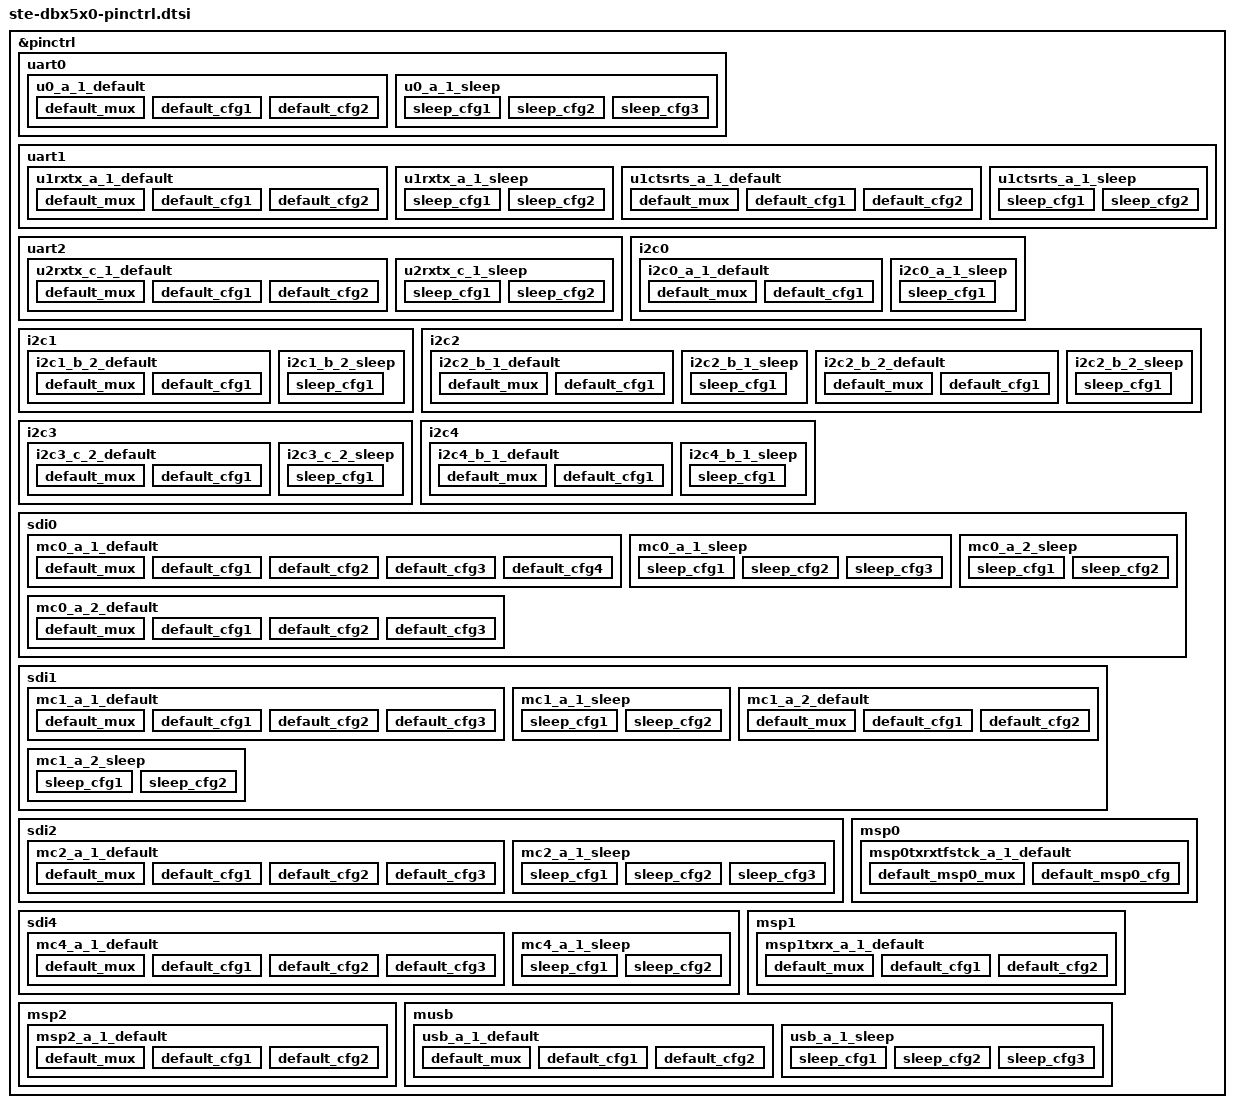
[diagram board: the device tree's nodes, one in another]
#include "ste-nomadik-pinctrl.dtsi"
&pinctrl {
	uart0 {
		u0_a_1_default: u0_a_1_default {
			default_mux {
				function = "u0";
				groups = "u0_a_1";
			};
			default_cfg1 {
				pins = "GPIO0_AJ5", "GPIO2_AH4";  
				ste,config = <&in_pu>;
			};
			default_cfg2 {
				pins = "GPIO1_AJ3", "GPIO3_AH3";  
				ste,config = <&out_hi>;
			};
		};
		u0_a_1_sleep: u0_a_1_sleep {
			sleep_cfg1 {
				pins = "GPIO0_AJ5", "GPIO2_AH4";  
				ste,config = <&slpm_in_wkup_pdis>;
			};
			sleep_cfg2 {
				pins = "GPIO1_AJ3";  
				ste,config = <&slpm_out_hi_wkup_pdis>;
			};
			sleep_cfg3 {
				pins = "GPIO3_AH3";  
				ste,config = <&slpm_out_wkup_pdis>;
			};
		};
	};
	uart1 {
		u1rxtx_a_1_default: u1rxtx_a_1_default {
			default_mux {
				function = "u1";
				groups = "u1rxtx_a_1";
			};
			default_cfg1 {
				pins = "GPIO4_AH6";  
				ste,config = <&in_pu>;
			};
			default_cfg2 {
				pins = "GPIO5_AG6";  
				ste,config = <&out_hi>;
			};
		};
		u1rxtx_a_1_sleep: u1rxtx_a_1_sleep {
			sleep_cfg1 {
				pins = "GPIO4_AH6";  
				ste,config = <&slpm_in_wkup_pdis>;
			};
			sleep_cfg2 {
				pins = "GPIO5_AG6";  
				ste,config = <&slpm_out_wkup_pdis>;
			};
		};
		u1ctsrts_a_1_default: u1ctsrts_a_1_default {
			default_mux {
				function = "u1";
				groups = "u1ctsrts_a_1";
			};
			default_cfg1 {
				pins = "GPIO6_AF6";  
				ste,config = <&in_pu>;
			};
			default_cfg2 {
				pins = "GPIO7_AG5";  
				ste,config = <&out_hi>;
			};
		};
		u1ctsrts_a_1_sleep: u1ctsrts_a_1_sleep {
			sleep_cfg1 {
				pins = "GPIO6_AF6";  
				ste,config = <&slpm_in_wkup_pdis>;
			};
			sleep_cfg2 {
				pins = "GPIO7_AG5";  
				ste,config = <&slpm_out_hi_wkup_pdis>;
			};
		};
	};
	uart2 {
		u2rxtx_c_1_default: u2rxtx_c_1_default {
			default_mux {
				function = "u2";
				groups = "u2rxtx_c_1";
			};
			default_cfg1 {
				pins = "GPIO29_W2";  
				ste,config = <&in_pu>;
			};
			default_cfg2 {
				pins = "GPIO30_W3";  
				ste,config = <&out_hi>;
			};
		};
		u2rxtx_c_1_sleep: u2rxtx_c_1_sleep {
			sleep_cfg1 {
				pins = "GPIO29_W2";  
				ste,config = <&in_wkup_pdis>;
			};
			sleep_cfg2 {
				pins = "GPIO30_W3";  
				ste,config = <&out_wkup_pdis>;
			};
		};
	};
	i2c0 {
		i2c0_a_1_default: i2c0_a_1_default {
			default_mux {
				function = "i2c0";
				groups = "i2c0_a_1";
			};
			default_cfg1 {
				pins = "GPIO147_C15", "GPIO148_B16";  
				ste,config = <&in_nopull>;
			};
		};
		i2c0_a_1_sleep: i2c0_a_1_sleep {
			sleep_cfg1 {
				pins = "GPIO147_C15", "GPIO148_B16";  
				ste,config = <&slpm_in_wkup_pdis>;
			};
		};
	};
	i2c1 {
		i2c1_b_2_default: i2c1_b_2_default {
			default_mux {
				function = "i2c1";
				groups = "i2c1_b_2";
			};
			default_cfg1 {
				pins = "GPIO16_AD3", "GPIO17_AD4";  
				ste,config = <&in_nopull>;
			};
		};
		i2c1_b_2_sleep: i2c1_b_2_sleep {
			sleep_cfg1 {
				pins = "GPIO16_AD3", "GPIO17_AD4";  
				ste,config = <&slpm_in_wkup_pdis>;
			};
		};
	};
	i2c2 {
		i2c2_b_1_default: i2c2_b_1_default {
			default_mux {
				function = "i2c2";
				groups = "i2c2_b_1";
			};
			default_cfg1 {
				pins = "GPIO8_AD5", "GPIO9_AE4";  
				ste,config = <&in_nopull>;
			};
		};
		i2c2_b_1_sleep: i2c2_b_1_sleep {
			sleep_cfg1 {
				pins = "GPIO8_AD5", "GPIO9_AE4";  
				ste,config = <&slpm_in_wkup_pdis>;
			};
		};
		i2c2_b_2_default: i2c2_b_2_default {
			default_mux {
				function = "i2c2";
				groups = "i2c2_b_2";
			};
			default_cfg1 {
				pins = "GPIO10_AF5", "GPIO11_AG4";  
				ste,config = <&in_nopull>;
			};
		};
		i2c2_b_2_sleep: i2c2_b_2_sleep {
			sleep_cfg1 {
				pins = "GPIO10_AF5", "GPIO11_AG4";  
				ste,config = <&slpm_in_wkup_pdis>;
			};
		};
	};
	i2c3 {
		i2c3_c_2_default: i2c3_c_2_default {
			default_mux {
				function = "i2c3";
				groups = "i2c3_c_2";
			};
			default_cfg1 {
				pins = "GPIO229_AG7", "GPIO230_AF7";  
				ste,config = <&in_nopull>;
			};
		};
		i2c3_c_2_sleep: i2c3_c_2_sleep {
			sleep_cfg1 {
				pins = "GPIO229_AG7", "GPIO230_AF7";  
				ste,config = <&slpm_in_wkup_pdis>;
			};
		};
	};
	i2c4 {
		i2c4_b_1_default: i2c4_b_1_default {
			default_mux {
				function = "i2c4";
				groups = "i2c4_b_1";
			};
			default_cfg1 {
				pins = "GPIO4_AH6", "GPIO5_AG6";  
				ste,config = <&in_nopull>;
			};
		};
		i2c4_b_1_sleep: i2c4_b_1_sleep {
			sleep_cfg1 {
				pins = "GPIO4_AH6", "GPIO5_AG6";  
				ste,config = <&slpm_in_wkup_pdis>;
			};
		};
	};
	sdi0 {
		mc0_a_1_default: mc0_a_1_default {
			default_mux {
				function = "mc0";
				groups = "mc0_a_1";
			};
			default_cfg1 {
				pins =
				"GPIO18_AC2",  
				"GPIO19_AC1",  
				"GPIO20_AB4";  
				ste,config = <&out_hi>;
			};
			default_cfg2 {
				pins = "GPIO22_AA3";  
				ste,config = <&in_nopull>;
			};
			default_cfg3 {
				pins = "GPIO23_AA4";  
				ste,config = <&out_lo>;
			};
			default_cfg4 {
				pins =
				"GPIO24_AB2",  
				"GPIO25_Y4",  
				"GPIO26_Y2",  
				"GPIO27_AA2",  
				"GPIO28_AA1";  
				ste,config = <&in_pu>;
			};
		};
		mc0_a_1_sleep: mc0_a_1_sleep {
			sleep_cfg1 {
				pins =
				"GPIO18_AC2",  
				"GPIO19_AC1",  
				"GPIO20_AB4";  
				ste,config = <&slpm_out_hi_wkup_pdis>;
			};
			sleep_cfg2 {
				pins =
				"GPIO22_AA3",  
				"GPIO24_AB2",  
				"GPIO25_Y4",  
				"GPIO26_Y2",  
				"GPIO27_AA2",  
				"GPIO28_AA1";  
				ste,config = <&slpm_in_wkup_pdis>;
			};
			sleep_cfg3 {
				pins = "GPIO23_AA4";  
				ste,config = <&slpm_out_lo_wkup_pdis>;
			};
		};
		mc0_a_2_default: mc0_a_2_default {
			default_mux {
				function = "mc0";
				groups = "mc0_a_2";
			};
			default_cfg1 {
				pins = "GPIO22_AA3";  
				ste,config = <&in_nopull>;
			};
			default_cfg2 {
				pins = "GPIO23_AA4";  
				ste,config = <&out_lo>;
			};
			default_cfg3 {
				pins =
				"GPIO24_AB2",  
				"GPIO25_Y4",  
				"GPIO26_Y2",  
				"GPIO27_AA2",  
				"GPIO28_AA1";  
				ste,config = <&in_pu>;
			};
		};
		mc0_a_2_sleep: mc0_a_2_sleep {
			sleep_cfg1 {
				pins =
				"GPIO22_AA3",  
				"GPIO24_AB2",  
				"GPIO25_Y4",  
				"GPIO26_Y2",  
				"GPIO27_AA2",  
				"GPIO28_AA1";  
				ste,config = <&slpm_in_wkup_pdis>;
			};
			sleep_cfg2 {
				pins = "GPIO23_AA4";  
				ste,config = <&slpm_out_lo_wkup_pdis>;
			};
		};
	};
	sdi1 {
		mc1_a_1_default: mc1_a_1_default {
			default_mux {
				function = "mc1";
				groups = "mc1_a_1";
			};
			default_cfg1 {
				pins = "GPIO208_AH16";  
				ste,config = <&out_lo>;
			};
			default_cfg2 {
				pins = "GPIO209_AG15";  
				ste,config = <&in_nopull>;
			};
			default_cfg3 {
				pins =
				"GPIO210_AJ15",  
				"GPIO211_AG14",  
				"GPIO212_AF13",  
				"GPIO213_AG13",  
				"GPIO214_AH15";  
				ste,config = <&in_pu>;
			};
		};
		mc1_a_1_sleep: mc1_a_1_sleep {
			sleep_cfg1 {
				pins = "GPIO208_AH16";  
				ste,config = <&slpm_out_lo_wkup_pdis>;
			};
			sleep_cfg2 {
				pins =
				"GPIO209_AG15",  
				"GPIO210_AJ15",  
				"GPIO211_AG14",  
				"GPIO212_AF13",  
				"GPIO213_AG13",  
				"GPIO214_AH15";  
				ste,config = <&slpm_in_wkup_pdis>;
			};
		};
		mc1_a_2_default: mc1_a_2_default {
			default_mux {
				function = "mc1";
				groups = "mc1_a_2";
			};
			default_cfg1 {
				pins = "GPIO208_AH16";  
				ste,config = <&out_lo>;
			};
			default_cfg2 {
				pins =
				"GPIO210_AJ15",  
				"GPIO211_AG14",  
				"GPIO212_AF13",  
				"GPIO213_AG13",  
				"GPIO214_AH15";  
				ste,config = <&in_pu>;
			};
		};
		mc1_a_2_sleep: mc1_a_2_sleep {
			sleep_cfg1 {
				pins = "GPIO208_AH16";  
				ste,config = <&slpm_out_lo_wkup_pdis>;
			};
			sleep_cfg2 {
				pins =
				"GPIO210_AJ15",  
				"GPIO211_AG14",  
				"GPIO212_AF13",  
				"GPIO213_AG13",  
				"GPIO214_AH15";  
				ste,config = <&slpm_in_wkup_pdis>;
			};
		};
	};
	sdi2 {
		mc2_a_1_default: mc2_a_1_default {
			default_mux {
				function = "mc2";
				groups = "mc2_a_1";
			};
			default_cfg1 {
				pins = "GPIO128_A5";  
				ste,config = <&out_lo>;
			};
			default_cfg2 {
				pins = "GPIO130_C8";  
				ste,config = <&in_nopull>;
			};
			default_cfg3 {
				pins =
				"GPIO129_B4",  
				"GPIO131_A12",  
				"GPIO132_C10",  
				"GPIO133_B10",  
				"GPIO134_B9",  
				"GPIO135_A9",  
				"GPIO136_C7",  
				"GPIO137_A7",  
				"GPIO138_C5";  
				ste,config = <&in_pu>;
			};
		};
		mc2_a_1_sleep: mc2_a_1_sleep {
			sleep_cfg1 {
				pins = "GPIO128_A5";  
				ste,config = <&out_lo_wkup_pdis>;
			};
			sleep_cfg2 {
				pins =
				"GPIO130_C8",  
				"GPIO129_B4";  
				ste,config = <&in_wkup_pdis_en>;
			};
			sleep_cfg3 {
				pins =
				"GPIO131_A12",  
				"GPIO132_C10",  
				"GPIO133_B10",  
				"GPIO134_B9",  
				"GPIO135_A9",  
				"GPIO136_C7",  
				"GPIO137_A7",  
				"GPIO138_C5";  
				ste,config = <&in_wkup_pdis>;
			};
		};
	};
	sdi4 {
		mc4_a_1_default: mc4_a_1_default {
			default_mux {
				function = "mc4";
				groups = "mc4_a_1";
			};
			default_cfg1 {
				pins = "GPIO203_AE23";  
				ste,config = <&out_lo>;
			};
			default_cfg2 {
				pins = "GPIO202_AF25";  
				ste,config = <&in_nopull>;
			};
			default_cfg3 {
				pins =
				"GPIO201_AF24",  
				"GPIO200_AH26",  
				"GPIO199_AH23",  
				"GPIO198_AG25",  
				"GPIO197_AH24",  
				"GPIO207_AJ23",  
				"GPIO206_AG24",  
				"GPIO205_AG23",  
				"GPIO204_AF23";  
				ste,config = <&in_pu>;
			};
		};
		mc4_a_1_sleep: mc4_a_1_sleep {
			sleep_cfg1 {
				pins = "GPIO203_AE23";  
				ste,config = <&out_lo_wkup_pdis>;
			};
			sleep_cfg2 {
				pins =
				"GPIO202_AF25",  
				"GPIO201_AF24",  
				"GPIO200_AH26",  
				"GPIO199_AH23",  
				"GPIO198_AG25",  
				"GPIO197_AH24",  
				"GPIO207_AJ23",  
				"GPIO206_AG24",  
				"GPIO205_AG23",  
				"GPIO204_AF23";  
				ste,config = <&slpm_in_wkup_pdis>;
			};
		};
	};
	msp0 {
		msp0txrxtfstck_a_1_default: msp0txrxtfstck_a_1_default {
			default_msp0_mux {
				function = "msp0";
				groups = "msp0txrx_a_1", "msp0tfstck_a_1";
			};
			default_msp0_cfg {
				pins =
				"GPIO12_AC4",  
				"GPIO15_AC3",  
				"GPIO13_AF3",  
				"GPIO14_AE3";  
				ste,config = <&in_nopull>;
			};
		};
	};
	msp1 {
		msp1txrx_a_1_default: msp1txrx_a_1_default {
			default_mux {
				function = "msp1";
				groups = "msp1txrx_a_1", "msp1_a_1";
			};
			default_cfg1 {
				pins = "GPIO33_AF2";
				ste,config = <&out_lo>;
			};
			default_cfg2 {
				pins =
				"GPIO34_AE1",
				"GPIO35_AE2",
				"GPIO36_AG2";
				ste,config = <&in_nopull>;
			};
		};
	};
	msp2 {
		msp2_a_1_default: msp2_a_1_default {
			default_mux {
				function = "msp2";
				groups = "msp2_a_1";
			};
			default_cfg1 {
				pins =
				"GPIO193_AH27",  
				"GPIO194_AF27",  
				"GPIO195_AG28";  
				ste,config = <&in_pd>;
			};
			default_cfg2 {
				pins = "GPIO196_AG26";  
				ste,config = <&out_lo>;
			};
		};
	};
	musb {
		usb_a_1_default: usb_a_1_default {
			default_mux {
				function = "usb";
				groups = "usb_a_1";
			};
			default_cfg1 {
				pins =
				"GPIO256_AF28",  
				"GPIO258_AD29",  
				"GPIO259_AC29",  
				"GPIO260_AD28",  
				"GPIO261_AD26",  
				"GPIO262_AE26",  
				"GPIO263_AG29",  
				"GPIO264_AE27",  
				"GPIO265_AD27",  
				"GPIO266_AC28",  
				"GPIO267_AC27";  
				ste,config = <&in_nopull>;
			};
			default_cfg2 {
				pins = "GPIO257_AE29";  
				ste,config = <&out_hi>;
			};
		};
		usb_a_1_sleep: usb_a_1_sleep {
			sleep_cfg1 {
				pins =
				"GPIO256_AF28",  
				"GPIO258_AD29",  
				"GPIO259_AC29";  
				ste,config = <&slpm_wkup_pdis_en>;
			};
			sleep_cfg2 {
				pins = "GPIO257_AE29";  
				ste,config = <&slpm_out_hi_wkup_pdis>;
			};
			sleep_cfg3 {
				pins =
				"GPIO260_AD28",  
				"GPIO261_AD26",  
				"GPIO262_AE26",  
				"GPIO263_AG29",  
				"GPIO264_AE27",  
				"GPIO265_AD27",  
				"GPIO266_AC28",  
				"GPIO267_AC27";  
				ste,config = <&slpm_in_wkup_pdis_en>;
			};
		};
	};
};
